# BugFindCPU register map
File version: 1.1
Borked CPU
Registers are 32-bit, read-write, reset 0x0 unless marked. A register's access mark holds for its fields unless they carry their own. Offsets are from the block's base; lines under a group give offsets from that group; [hi:lo] are bit positions; {n}, {i} and the like mark numbered series; 'fields as' and 'values as' point back to an identical list; <NAME> marks a mode.

## Memory map
0x12343210 BFT size 0x400 — Bug Find Test

## Interrupts
42 BUG (BFT) — A realy buggy interrupt

## BFT — Bug Find Test
Base 0x12343210
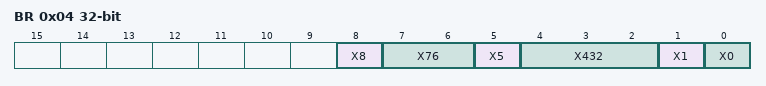
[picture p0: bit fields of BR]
0x04 BR — test register
  [8] X8 — Bit 8
  [7:6] X76 — Bits 7:6
  [5] X5 — Bit 5
  [4:2] X432 — Bits 4:2
  [1] X1 — Bit One
  [0] X0 — Bit Zero
0x08 DDR ro — dummy data register
  [31:0] DDDATA — Random data in randomness
